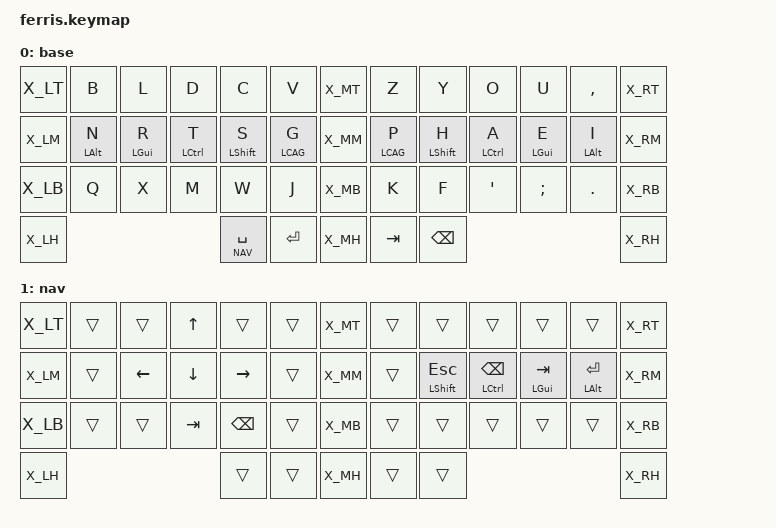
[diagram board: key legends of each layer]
#include <behaviors.dtsi>
/* source keypos definitions */
#include "../zmk-nodefree-config/keypos_def/keypos_34keys.h"

#include "../zmk-nodefree-config/helper.h"

#include "extra_keys.h"

#define XXX &none
#define ___ &trans

#define QUICK_TAP_MS 175

&lt {  // layer-tap config
    flavor = "balanced";
    tapping-term-ms = <200>;
    quick-tap-ms = <QUICK_TAP_MS>;
};


#define DEF 0
#define NAV 1

#define KEYS_L LT0 LT1 LT2 LT3 LT4 LM0 LM1 LM2 LM3 LM4 LB0 LB1 LB2 LB3 LB4  // left hand
#define KEYS_R RT0 RT1 RT2 RT3 RT4 RM0 RM1 RM2 RM3 RM4 RB0 RB1 RB2 RB3 RB4  // right hand
#define THUMBS LH1 LH0 RH0 RH1                                              // thumbs

#define MAKE_HRM(NAME, HOLD, TAP, TRIGGER_POS) \
    ZMK_BEHAVIOR(NAME, hold_tap, \
        flavor = "balanced"; \
        tapping-term-ms = <280>; \
        quick-tap-ms = <QUICK_TAP_MS>; \
        require-prior-idle-ms = <150>; \
        bindings = <HOLD>, <TAP>; \
        hold-trigger-key-positions = <TRIGGER_POS>; \
        hold-trigger-on-release; \
    )
MAKE_HRM(hml, &kp, &kp, KEYS_R THUMBS)  // left-hand HRMs
MAKE_HRM(hmr, &kp, &kp, KEYS_L THUMBS)  // right-hand HRMs

#define LCAG LC(LA(LGUI))

ZMK_LAYER(base,
//╭──────╮ ─────────────┬─────────────┬─────────────┬─────────────┬─────────────╮ ╭──────╮ ─────────────┬─────────────┬─────────────┬─────────────┬───────────── ╭──────╮
    X_LT    &kp B         &kp L         &kp D         &kp C         &kp V           X_MT    &kp Z         &kp Y         &kp O         &kp U         &kp COMMA      X_RT
//├──────┤ ─────────────┼─────────────┼─────────────┼─────────────┼─────────────┤ ├──────┤ ─────────────┼─────────────┼─────────────┼─────────────┼───────────── ├──────┤
    X_LM    &hml LALT N   &hml LGUI R   &hml LCTRL T  &hml LSHFT S  &hml LCAG G     X_MM    &hmr LCAG P   &hmr LSHFT H  &hmr LCTRL A  &hmr LGUI E   &hmr LALT I    X_RM
//├──────┤ ─────────────┼─────────────┼─────────────┼─────────────┼─────────────┤ ├──────┤ ─────────────┼─────────────┼─────────────┼─────────────┼───────────── ├──────┤
    X_LB    &kp Q         &kp X         &kp M         &kp W         &kp J           X_MB    &kp K         &kp F         &kp SQT      &kp SEMI      &kp DOT         X_RB
//├──────┤ ─────────────┼─────────────┴─────────────┼─────────────┼─────────────┤ ├──────┤ ─────────────┼─────────────┼─────────────┴─────────────┼───────────── ├──────┤
    X_LH                                              &lt NAV SPACE &kp ENTER       X_MH    &kp TAB       &kp BSPC                                                 X_RH
//╰──────╯                                          ╰─────────────┴─────────────╯ ╰──────╯ ─────────────┴─────────────╯                                          ╰──────╯
)

ZMK_LAYER(nav,
//╭──────╮ ╭─────────────┬─────────────┬─────────────┬─────────────┬─────────────╮ ╭──────╮ ╭─────────────┬────────────────┬──────────────────┬────────────────┬──────────────────╮ ╭──────╮
    X_LT     ___           ___           &kp UP        ___           ___             X_MT     ___           ___              ___                ___              ___                  X_RT
//├──────┤ ├─────────────┼─────────────┼─────────────┼─────────────┼─────────────┤ ├──────┤ ├─────────────┼────────────────┼──────────────────┼────────────────┼──────────────────┤ ├──────┤
    X_LM     ___           &kp LEFT      &kp DOWN      &kp RIGHT     ___             X_MM     ___           &hmr LSHFT ESC   &hmr LCTRL BSPC    &hmr LGUI TAB    &hmr LALT ENTER      X_RM
//├──────┤ ├─────────────┼─────────────┼─────────────┼─────────────┼─────────────┤ ├──────┤ ├─────────────┼────────────────┼──────────────────┼────────────────┼──────────────────┤ ├──────┤
    X_LB     ___           ___           &kp TAB       &kp BSPC      ___             X_MB     ___           ___              ___                ___              ___                  X_RB
//├──────┤ ╰─────────────┼─────────────┴─────────────┼─────────────┼─────────────┤ ├──────┤ ├─────────────┼────────────────┼──────────────────┴────────────────┴──────────────────╯ ├──────┤
    X_LH                                               ___           ___             X_MH     ___           ___                                                                       X_RH
//╰──────╯                                           ╰─────────────┴─────────────╯ ╰──────╯ ╰─────────────┴────────────────╯                                                        ╰──────╯
)

// ZMK_LAYER(sym,
// //╭──────╮ ╭─────────────┬─────────────┬─────────────┬─────────────┬─────────────╮ ╭──────╮ ╭─────────────┬─────────────┬─────────────┬─────────────┬─────────────╮ ╭──────╮
//     X_LT     ___           ___           ___           ___           ___             X_MT     ___           ___           ___           ___           ___             X_RT
// //├──────┤ ├─────────────┼─────────────┼─────────────┼─────────────┼─────────────┤ ├──────┤ ├─────────────┼─────────────┼─────────────┼─────────────┼─────────────┤ ├──────┤
//     X_LM     ___           ___           ___           ___           ___             X_MM     ___           ___           ___           ___           ___             X_RM
// //├──────┤ ├─────────────┼─────────────┼─────────────┼─────────────┼─────────────┤ ├──────┤ ├─────────────┼─────────────┼─────────────┼─────────────┼─────────────┤ ├──────┤
//     X_LB     ___           ___           ___           ___           ___             X_MB     ___           ___           ___           ___           ___             X_RB
// //├──────┤ ╰─────────────┼─────────────┴─────────────┼─────────────┼─────────────┤ ├──────┤ ├─────────────┼─────────────┼─────────────┴─────────────┴─────────────╯ ├──────┤
//     X_LH                                               ___           ___             X_MH     ___           ___                                                       X_RH
// //╰──────╯                                           ╰─────────────┴─────────────╯ ╰──────╯ ╰─────────────┴─────────────╯                                           ╰──────╯
// )


/* vim: set ft=c tw=174: */
